# MSP432P4111 register map
Vendor: Texas Instruments; File version: 3.230
Registers are 32-bit, read-write, reset 0x0 unless marked. A register's access mark holds for its fields unless they carry their own. Offsets are from the block's base; [hi:lo] are bit positions.

## REF_A
Base 0x40003000
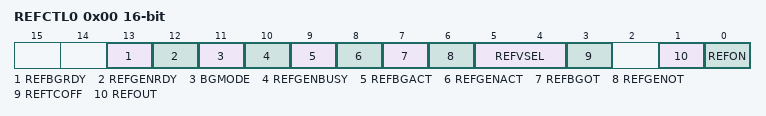
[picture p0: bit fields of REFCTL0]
0x00 REFCTL0 16-bit reset not defined — REF Control Register 0
  [13] REFBGRDY ro — Buffered bandgap voltage ready status
    on read: 0=Buffered bandgap voltage is not ready to be used; 1=Buffered bandgap voltage is ready to be used
  [12] REFGENRDY ro — Variable reference voltage ready status
    on read: 0=Reference voltage output is not ready to be used; 1=Reference voltage output is ready to be used
  [11] BGMODE ro — Bandgap mode
    on read: 0=Static mode; 1=Sampled mode
  [10] REFGENBUSY ro — Reference generator busy
    on read: 0=Reference generator not busy; 1=Reference generator busy
  [9] REFBGACT ro — Reference bandgap active
    on read: 0=Reference bandgap buffer not active; 1=Reference bandgap buffer active
  [8] REFGENACT ro — Reference generator active
    on read: 0=Reference generator not active; 1=Reference generator active
  [7] REFBGOT — Bandgap and bandgap buffer one-time trigger
    0=No trigger; 1=Generation of the bandgap voltage is started by writing 1 or by a hardware trigger
  [6] REFGENOT — Reference generator one-time trigger
    0=No trigger; 1=Generation of the reference voltage is started by writing 1 or by a hardware trigger
  [5:4] REFVSEL — Reference voltage level select
    0=1.2 V available when reference requested or REFON = 1; 1=1.45 V available when reference requested or REFON = 1; 3=2.5 V available when reference requested or REFON = 1
  [3] REFTCOFF — Temperature sensor disabled
    0=Temperature sensor enabled; 1=Temperature sensor disabled to save power
  [1] REFOUT — Reference output buffer
    0=Reference output not available externally; 1=Reference output available externally. If ADC14REFBURST = 0, output is available continuously. If ADC14REFBURST = 1, output is available only during an ADC14 conversion.
  [0] REFON — Reference enable
    0=Disables reference if no other reference requests are pending; 1=Enables reference in static mode

## AES256
Base 0x40003C00
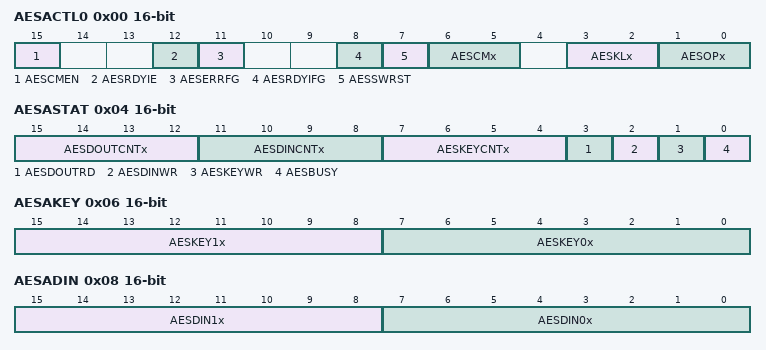
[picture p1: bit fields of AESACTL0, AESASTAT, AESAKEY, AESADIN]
0x00 AESACTL0 16-bit — AES Accelerator Control Register 0
  [15] AESCMEN — AES cipher mode enable
    0=No DMA triggers are generated; 1=DMA ciphermode support operation is enabled and the corresponding DMA triggers are generated
  [12] AESRDYIE — AES ready interrupt enable
    0=Interrupt disabled; 1=Interrupt enabled
  [11] AESERRFG — AES error flag
    0=No error; 1=Error occurred
  [8] AESRDYIFG — AES ready interrupt flag
    0=No interrupt pending; 1=Interrupt pending
  [7] AESSWRST — AES software reset
    0=No reset; 1=Reset AES accelerator module
  [6:5] AESCMx — AES cipher mode select
    0=ECB; 1=CBC; 2=OFB; 3=CFB
  [3:2] AESKLx — AES key length
    0=AES128. The key size is 128 bit; 1=AES192. The key size is 192 bit.; 2=AES256. The key size is 256 bit
  [1:0] AESOPx — AES operation
    0=Encryption; 1=Decryption. The provided key is the same key used for encryption; 2=Generate first round key required for decryption; 3=Decryption. The provided key is the first round key required for decryption
0x02 AESACTL1 16-bit — AES Accelerator Control Register 1
  [7:0] AESBLKCNTx — Cipher Block Counter
0x04 AESASTAT 16-bit — AES Accelerator Status Register
  [15:12] AESDOUTCNTx ro — Bytes read via AESADOUT
  [11:8] AESDINCNTx ro — Bytes written via AESADIN, AESAXDIN or AESAXIN
  [7:4] AESKEYCNTx ro — Bytes written via AESAKEY for AESKLx=00, half-words written via AESAKEY
  [3] AESDOUTRD ro — All 16 bytes read from AESADOUT
    on read: 0=Not all bytes read; 1=All bytes read
  [2] AESDINWR — All 16 bytes written to AESADIN, AESAXDIN or AESAXIN
    0=Not all bytes written; 1=All bytes written
  [1] AESKEYWR — All 16 bytes written to AESAKEY
    0=Not all bytes written; 1=All bytes written
  [0] AESBUSY — AES accelerator module busy
    0=Not busy; 1=Busy
0x06 AESAKEY 16-bit wo — AES Accelerator Key Register
  [15:8] AESKEY1x — AES key byte n+1 when AESAKEY is written as half-word
  [7:0] AESKEY0x — AES key byte n when AESAKEY is written as half-word
0x08 AESADIN 16-bit wo — AES Accelerator Data In Register
  [15:8] AESDIN1x — AES data in byte n+1 when AESADIN is written as half-word
  [7:0] AESDIN0x — AES data in byte n when AESADIN is written as half-word
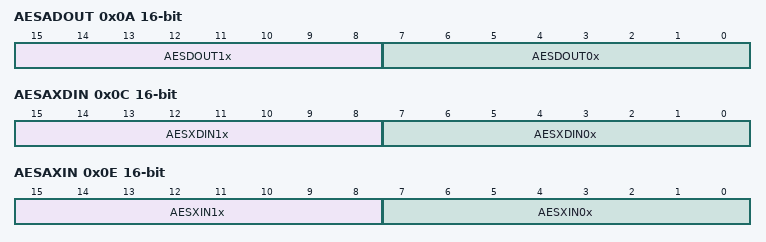
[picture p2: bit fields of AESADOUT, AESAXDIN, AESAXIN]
0x0A AESADOUT 16-bit wo — AES Accelerator Data Out Register
  [15:8] AESDOUT1x — AES data out byte n+1 when AESADOUT is read as half-word
  [7:0] AESDOUT0x — AES data out byte n when AESADOUT is read as half-word
0x0C AESAXDIN 16-bit wo — AES Accelerator XORed Data In Register
  [15:8] AESXDIN1x — AES data in byte n+1 when AESAXDIN is written as half-word
  [7:0] AESXDIN0x — AES data in byte n when AESAXDIN is written as half-word
0x0E AESAXIN 16-bit wo — AES Accelerator XORed Data In Register
  [15:8] AESXIN1x — AES data in byte n+1 when AESAXIN is written as half-word
  [7:0] AESXIN0x — AES data in byte n when AESAXIN is written as half-word

## Notices in the file
Copyright (C) 2012-2018 Texas Instruments Incorporated - http://www.ti.com
Redistribution and use in source and binary forms, with or without
modification, are permitted provided that the following conditions
are met:
Redistributions of source code must retain the above copyright
notice, this list of conditions and the following disclaimer.
Redistributions in binary form must reproduce the above copyright
notice, this list of conditions and the following disclaimer in the
documentation and/or other materials provided with the
distribution.
Neither the name of Texas Instruments Incorporated nor the names of
its contributors may be used to endorse or promote products derived
from this software without specific prior written permission.
THIS SOFTWARE IS PROVIDED BY THE COPYRIGHT HOLDERS AND CONTRIBUTORS
"AS IS" AND ANY EXPRESS OR IMPLIED WARRANTIES, INCLUDING, BUT NOT
LIMITED TO, THE IMPLIED WARRANTIES OF MERCHANTABILITY AND FITNESS FOR
A PARTICULAR PURPOSE ARE DISCLAIMED. IN NO EVENT SHALL THE COPYRIGHT
OWNER OR CONTRIBUTORS BE LIABLE FOR ANY DIRECT, INDIRECT, INCIDENTAL,
SPECIAL, EXEMPLARY, OR CONSEQUENTIAL DAMAGES (INCLUDING, BUT NOT
LIMITED TO, PROCUREMENT OF SUBSTITUTE GOODS OR SERVICES; LOSS OF USE,
DATA, OR PROFITS; OR BUSINESS INTERRUPTION) HOWEVER CAUSED AND ON ANY
THEORY OF LIABILITY, WHETHER IN CONTRACT, STRICT LIABILITY, OR TORT
(INCLUDING NEGLIGENCE OR OTHERWISE) ARISING IN ANY WAY OUT OF THE USE
OF THIS SOFTWARE, EVEN IF ADVISED OF THE POSSIBILITY OF SUCH DAMAGE.
